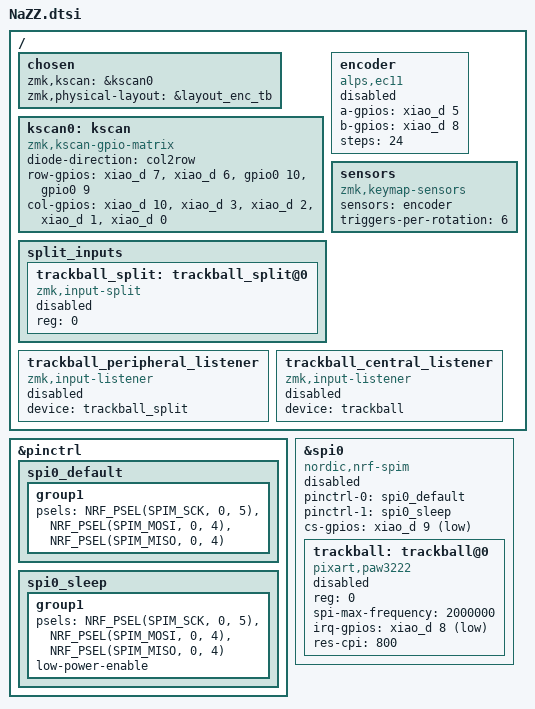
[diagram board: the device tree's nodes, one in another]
#include <dt-bindings/zmk/matrix_transform.h>
#include <dt-bindings/zmk/input_transform.h>
#include <zephyr/dt-bindings/input/input-event-codes.h>
#include <input/processors.dtsi>
#include "NaZZ-layouts.dtsi"

// 左右共通基板。モジュール（エンコーダ／トラボ）の部品はここで定義だけして無効にしておき、
// snippet（nazz-encoder / nazz-trackball-* / nazz-layout-*）で構成ごとに有効にする。
//
// ピン（基板 NaZZ.kicad_pcb より）
//   Row0=D7 Row1=D6 Row2=P0.10(NFC2) Row3=P0.09(NFC1) Row4=D9(エンコーダ構成のみ)
//   Col0=D10 Col1=D3 Col2=D2 Col3=D1 Col4=D0
//   はんだジャンパで切り替える3本: D5=RE_A/SCLK  D8=RE_B/MOT  D9=Row4/NCS  （D4=SDIO専用）

/ {
    chosen {
        zmk,kscan = &kscan0;
        zmk,physical-layout = &layout_enc_tb;  // 既定。nazz-layout-* snippet で上書き
    };

    kscan0: kscan {
        compatible = "zmk,kscan-gpio-matrix";
        diode-direction = "col2row";
        row-gpios
            = <&xiao_d 7 (GPIO_ACTIVE_HIGH | GPIO_PULL_DOWN)>   // Row0
            , <&xiao_d 6 (GPIO_ACTIVE_HIGH | GPIO_PULL_DOWN)>   // Row1
            , <&gpio0 10 (GPIO_ACTIVE_HIGH | GPIO_PULL_DOWN)>   // Row2 (NFC2)
            , <&gpio0 9  (GPIO_ACTIVE_HIGH | GPIO_PULL_DOWN)>   // Row3 (NFC1)
            ;
        col-gpios
            = <&xiao_d 10 GPIO_ACTIVE_HIGH>                     // Col0
            , <&xiao_d 3  GPIO_ACTIVE_HIGH>                     // Col1
            , <&xiao_d 2  GPIO_ACTIVE_HIGH>                     // Col2
            , <&xiao_d 1  GPIO_ACTIVE_HIGH>                     // Col3
            , <&xiao_d 0  GPIO_ACTIVE_HIGH>                     // Col4
            ;
    };

    // エンコーダ（各手に1つまで。押し込みはSW16と同じ Row3 Col0）
    encoder: encoder {
        compatible = "alps,ec11";
        a-gpios = <&xiao_d 5 (GPIO_ACTIVE_HIGH | GPIO_PULL_UP)>;  // RE_A
        b-gpios = <&xiao_d 8 (GPIO_ACTIVE_HIGH | GPIO_PULL_UP)>;  // RE_B
        steps = <24>;
        status = "disabled";
    };

    sensors: sensors {
        compatible = "zmk,keymap-sensors";
        sensors = <&encoder>;
        triggers-per-rotation = <6>;  // Enigma_01_Proと同じ
    };

    // 右手（peripheral）のトラボを左手（central）へ中継する
    split_inputs {
        #address-cells = <1>;
        #size-cells = <0>;

        trackball_split: trackball_split@0 {
            compatible = "zmk,input-split";
            reg = <0>;
            status = "disabled";
        };
    };

    // 右手トラボを左手で受ける listener
    // 向きの補正・ジェスチャー・オートマウスなどの input-processors はキーマップ側で設定する
    trackball_peripheral_listener: trackball_peripheral_listener {
        compatible = "zmk,input-listener";
        status = "disabled";
        device = <&trackball_split>;
    };

    // 左手トラボ（central に直結）の listener
    trackball_central_listener: trackball_central_listener {
        compatible = "zmk,input-listener";
        status = "disabled";
        device = <&trackball>;
    };
};

// トラボ（PAW3222）: SCLK=D5(P0.05) SDIO=D4(P0.04) NCS=D9 MOT=D8
&pinctrl {
    spi0_default: spi0_default {
        group1 {
            psels = <NRF_PSEL(SPIM_SCK, 0, 5)>,
                <NRF_PSEL(SPIM_MOSI, 0, 4)>,    // SDIOは1本でMOSI/MISOを兼ねる
                <NRF_PSEL(SPIM_MISO, 0, 4)>;
        };
    };

    spi0_sleep: spi0_sleep {
        group1 {
            psels = <NRF_PSEL(SPIM_SCK, 0, 5)>,
                <NRF_PSEL(SPIM_MOSI, 0, 4)>,
                <NRF_PSEL(SPIM_MISO, 0, 4)>;
            low-power-enable;
        };
    };
};

&spi0 {
    status = "disabled";
    compatible = "nordic,nrf-spim";
    pinctrl-0 = <&spi0_default>;
    pinctrl-1 = <&spi0_sleep>;
    pinctrl-names = "default", "sleep";
    cs-gpios = <&xiao_d 9 GPIO_ACTIVE_LOW>;  // NCS

    trackball: trackball@0 {
        compatible = "pixart,paw3222";
        reg = <0>;
        spi-max-frequency = <2000000>;
        irq-gpios = <&xiao_d 8 (GPIO_ACTIVE_LOW | GPIO_PULL_UP)>;  // MOT
        res-cpi = <800>;
        status = "disabled";
    };
};
